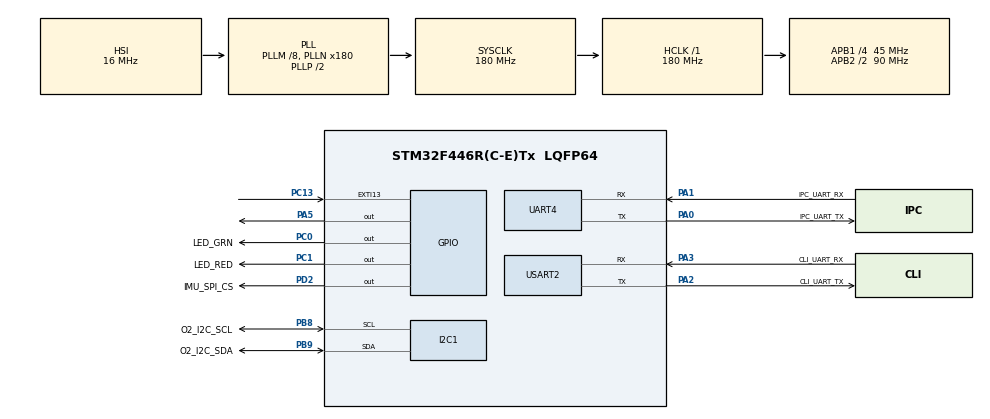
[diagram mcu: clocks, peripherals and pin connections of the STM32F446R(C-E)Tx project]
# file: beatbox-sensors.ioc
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Dma.I2C1_RX.3.Direction=DMA_PERIPH_TO_MEMORY
Dma.I2C1_RX.3.FIFOMode=DMA_FIFOMODE_DISABLE
Dma.I2C1_RX.3.Instance=DMA1_Stream0
Dma.I2C1_RX.3.MemDataAlignment=DMA_MDATAALIGN_BYTE
Dma.I2C1_RX.3.MemInc=DMA_MINC_ENABLE
Dma.I2C1_RX.3.Mode=DMA_NORMAL
Dma.I2C1_RX.3.PeriphDataAlignment=DMA_PDATAALIGN_BYTE
Dma.I2C1_RX.3.PeriphInc=DMA_PINC_DISABLE
Dma.I2C1_RX.3.Priority=DMA_PRIORITY_LOW
Dma.I2C1_TX.4.Direction=DMA_MEMORY_TO_PERIPH
Dma.I2C1_TX.4.FIFOMode=DMA_FIFOMODE_DISABLE
Dma.I2C1_TX.4.Instance=DMA1_Stream7
Dma.I2C1_TX.4.MemDataAlignment=DMA_MDATAALIGN_BYTE
Dma.I2C1_TX.4.MemInc=DMA_MINC_ENABLE
Dma.I2C1_TX.4.Mode=DMA_NORMAL
Dma.I2C1_TX.4.PeriphDataAlignment=DMA_PDATAALIGN_BYTE
Dma.I2C1_TX.4.PeriphInc=DMA_PINC_DISABLE
Dma.I2C1_TX.4.Priority=DMA_PRIORITY_LOW
Dma.Request0=USART2_RX
Dma.Request1=USART2_TX
Dma.Request2=UART4_TX
Dma.Request3=I2C1_RX
Dma.Request4=I2C1_TX
Dma.UART4_TX.2.Direction=DMA_MEMORY_TO_PERIPH
Dma.UART4_TX.2.FIFOMode=DMA_FIFOMODE_DISABLE
Dma.UART4_TX.2.Instance=DMA1_Stream4
Dma.UART4_TX.2.MemDataAlignment=DMA_MDATAALIGN_BYTE
Dma.UART4_TX.2.MemInc=DMA_MINC_ENABLE
Dma.UART4_TX.2.Mode=DMA_NORMAL
Dma.UART4_TX.2.PeriphDataAlignment=DMA_PDATAALIGN_BYTE
Dma.UART4_TX.2.PeriphInc=DMA_PINC_DISABLE
Dma.UART4_TX.2.Priority=DMA_PRIORITY_LOW
Dma.USART2_RX.0.Direction=DMA_PERIPH_TO_MEMORY
Dma.USART2_RX.0.FIFOMode=DMA_FIFOMODE_DISABLE
Dma.USART2_RX.0.Instance=DMA1_Stream5
Dma.USART2_RX.0.MemDataAlignment=DMA_MDATAALIGN_BYTE
Dma.USART2_RX.0.MemInc=DMA_MINC_ENABLE
Dma.USART2_RX.0.Mode=DMA_NORMAL
Dma.USART2_RX.0.PeriphDataAlignment=DMA_PDATAALIGN_BYTE
Dma.USART2_RX.0.PeriphInc=DMA_PINC_DISABLE
Dma.USART2_RX.0.Priority=DMA_PRIORITY_LOW
Dma.USART2_TX.1.Direction=DMA_MEMORY_TO_PERIPH
Dma.USART2_TX.1.FIFOMode=DMA_FIFOMODE_DISABLE
Dma.USART2_TX.1.Instance=DMA1_Stream6
Dma.USART2_TX.1.MemDataAlignment=DMA_MDATAALIGN_BYTE
Dma.USART2_TX.1.MemInc=DMA_MINC_ENABLE
Dma.USART2_TX.1.Mode=DMA_NORMAL
Dma.USART2_TX.1.PeriphDataAlignment=DMA_PDATAALIGN_BYTE
Dma.USART2_TX.1.PeriphInc=DMA_PINC_DISABLE
Dma.USART2_TX.1.Priority=DMA_PRIORITY_LOW
Mcu.Family=STM32F4
Mcu.Name=STM32F446R(C-E)Tx
Mcu.Package=LQFP64
NUCLEO-F446RE.BUTTON=1
NUCLEO-F446RE.LD1=true
NVIC.DMA1_Stream0_IRQn=true\:0\:0\:false\:false\:true\:false\:true\:true
NVIC.DMA1_Stream4_IRQn=true\:0\:0\:false\:false\:true\:false\:true\:true
NVIC.DMA1_Stream5_IRQn=true\:0\:0\:false\:false\:true\:false\:true\:true
NVIC.DMA1_Stream6_IRQn=true\:0\:0\:false\:false\:true\:false\:true\:true
NVIC.DMA1_Stream7_IRQn=true\:0\:0\:false\:false\:true\:false\:true\:true
NVIC.EXTI15_10_IRQn=true\:0\:0\:false\:false\:true\:false\:true\:true
NVIC.I2C1_ER_IRQn=true\:0\:0\:false\:false\:true\:true\:true\:true
NVIC.I2C1_EV_IRQn=true\:0\:0\:false\:false\:true\:true\:true\:true
NVIC.PriorityGroup=NVIC_PRIORITYGROUP_0
NVIC.UART4_IRQn=true\:0\:0\:false\:false\:true\:true\:true\:true
NVIC.USART2_IRQn=true\:0\:0\:false\:false\:true\:true\:true\:true
PA0-WKUP.GPIO_Label=IPC_UART_TX
PA0-WKUP.Mode=Asynchronous
PA0-WKUP.Signal=UART4_TX
PA1.GPIO_Label=IPC_UART_RX
PA1.Mode=Asynchronous
PA1.Signal=UART4_RX
PA13.GPIO_Label=TMS
PA13.Mode=Trace_Asynchronous_SW
PA13.Signal=SYS_JTMS-SWDIO
PA14.GPIO_Label=TCK
PA14.Mode=Trace_Asynchronous_SW
PA14.Signal=SYS_JTCK-SWCLK
PA2.GPIO_Label=CLI_UART_TX
PA2.Mode=Asynchronous
PA2.Signal=USART2_TX
PA3.GPIO_Label=CLI_UART_RX
PA3.Mode=Asynchronous
PA3.Signal=USART2_RX
PA5.Signal=GPIO_Output
PB3.GPIO_Label=SWO
PB3.Mode=Trace_Asynchronous_SW
PB3.Signal=SYS_JTDO-SWO
PB8.GPIO_Label=O2_I2C_SCL
PB8.Mode=I2C
PB8.Signal=I2C1_SCL
PB9.GPIO_Label=O2_I2C_SDA
PB9.Mode=I2C
PB9.Signal=I2C1_SDA
PC0.GPIO_Label=LED_GRN
PC0.Signal=GPIO_Output
PC1.GPIO_Label=LED_RED
PC1.Signal=GPIO_Output
PC10.GPIO_Label=IMU_SPI_CLK
PC10.Signal=SPI3_SCK
PC11.GPIO_Label=IMU_SPI_MISO
PC11.Signal=SPI3_MISO
PC12.GPIO_Label=IMU_SPI_MOSI
PC12.Signal=SPI3_MOSI
PC13.Signal=GPXTI13
PD2.GPIO_Label=IMU_SPI_CS
PD2.Signal=GPIO_Output
ProjectManager.HeapSize=0x200
ProjectManager.StackSize=0x400
ProjectManager.TargetToolchain=CMake
RCC.AHBFreq_Value=180000000
RCC.APB1CLKDivider=RCC_HCLK_DIV4
RCC.APB1Freq_Value=45000000
RCC.APB1TimFreq_Value=90000000
RCC.APB2CLKDivider=RCC_HCLK_DIV2
RCC.APB2Freq_Value=90000000
RCC.APB2TimFreq_Value=180000000
RCC.CortexFreq_Value=180000000
RCC.FLatency-AdvancedSettings=FLASH_LATENCY_5
RCC.HCLKFreq_Value=180000000
RCC.HSE_VALUE=8000000
RCC.HSI_VALUE=16000000
RCC.LSE_VALUE=32768
RCC.PLLM=8
RCC.PLLN=180
RCC.SYSCLKFreq_VALUE=180000000
RCC.SYSCLKSource=RCC_SYSCLKSOURCE_PLLCLK
RCC.USBFreq_Value=180000000
RCC.VCOOutputFreq_Value=360000000
UART4.VirtualMode=Asynchronous
USART2.VirtualMode=VM_ASYNC
VP_NUCLEO-F446RE_VS_BSP_COMMON.Mode=COMMON
board=NUCLEO-F446RE

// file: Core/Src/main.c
/* USER CODE BEGIN Header */
/**
 ******************************************************************************
 * @file           : main.c
 * @brief          : Main program body
 ******************************************************************************
 * @attention
 *
 * Copyright (c) 2026 STMicroelectronics.
 * All rights reserved.
 *
 * This software is licensed under terms that can be found in the LICENSE file
 * in the root directory of this software component.
 * If no LICENSE file comes with this software, it is provided AS-IS.
 *
 ******************************************************************************
 */
/* USER CODE END Header */
#include "main.h"
#include "dma.h"
#include "i2c.h"
#include "usart.h"
#include "gpio.h"

/* USER CODE BEGIN Includes */
#include "app/app.hpp"
/* USER CODE END Includes */

void SystemClock_Config(void);

int main(void)
{

  /* MCU Configuration--------------------------------------------------------*/

  /* Reset of all peripherals, Initializes the Flash interface and the Systick. */
  HAL_Init();

  /* Configure the system clock */
  SystemClock_Config();

  /* Initialize all configured peripherals */
  MX_GPIO_Init();
  MX_DMA_Init();
  MX_I2C1_Init();
  MX_USART2_UART_Init();
  MX_UART4_Init();
  /* USER CODE BEGIN 2 */
  appInit();
  /* USER CODE END 2 */

  /* Initialize leds */
  BSP_LED_Init(LED2);

  /* Initialize USER push-button, will be used to trigger an interrupt each time it's pressed.*/
  BSP_PB_Init(BUTTON_USER, BUTTON_MODE_EXTI);

  /* Infinite loop */
  /* USER CODE BEGIN WHILE */
  while (1) {
    appRun();
    /* USER CODE END WHILE */

  }
}

void SystemClock_Config(void)
{
  RCC_OscInitTypeDef RCC_OscInitStruct = {0};
  RCC_ClkInitTypeDef RCC_ClkInitStruct = {0};

  /** Configure the main internal regulator output voltage
  */
  __HAL_RCC_PWR_CLK_ENABLE();
  __HAL_PWR_VOLTAGESCALING_CONFIG(PWR_REGULATOR_VOLTAGE_SCALE1);

  /** Initializes the RCC Oscillators according to the specified parameters
  * in the RCC_OscInitTypeDef structure.
  */
  RCC_OscInitStruct.OscillatorType = RCC_OSCILLATORTYPE_HSI;
  RCC_OscInitStruct.HSIState = RCC_HSI_ON;
  RCC_OscInitStruct.HSICalibrationValue = RCC_HSICALIBRATION_DEFAULT;
  RCC_OscInitStruct.PLL.PLLState = RCC_PLL_ON;
  RCC_OscInitStruct.PLL.PLLSource = RCC_PLLSOURCE_HSI;
  RCC_OscInitStruct.PLL.PLLM = 8;
  RCC_OscInitStruct.PLL.PLLN = 180;
  RCC_OscInitStruct.PLL.PLLP = RCC_PLLP_DIV2;
  RCC_OscInitStruct.PLL.PLLQ = 2;
  RCC_OscInitStruct.PLL.PLLR = 2;
  if (HAL_RCC_OscConfig(&RCC_OscInitStruct) != HAL_OK)
  {
    Error_Handler();
  }

  /** Activate the Over-Drive mode
  */
  if (HAL_PWREx_EnableOverDrive() != HAL_OK)
  {
    Error_Handler();
  }

  /** Initializes the CPU, AHB and APB buses clocks
  */
  RCC_ClkInitStruct.ClockType = RCC_CLOCKTYPE_HCLK|RCC_CLOCKTYPE_SYSCLK
                              |RCC_CLOCKTYPE_PCLK1|RCC_CLOCKTYPE_PCLK2;
  RCC_ClkInitStruct.SYSCLKSource = RCC_SYSCLKSOURCE_PLLCLK;
  RCC_ClkInitStruct.AHBCLKDivider = RCC_SYSCLK_DIV1;
  RCC_ClkInitStruct.APB1CLKDivider = RCC_HCLK_DIV4;
  RCC_ClkInitStruct.APB2CLKDivider = RCC_HCLK_DIV2;

  if (HAL_RCC_ClockConfig(&RCC_ClkInitStruct, FLASH_LATENCY_5) != HAL_OK)
  {
    Error_Handler();
  }
}

void Error_Handler(void)
{
  /* USER CODE BEGIN Error_Handler_Debug */
  /* User can add his own implementation to report the HAL error return state */
  __disable_irq();
  for (;;) {
    HAL_GPIO_TogglePin(LED2_GPIO_PORT, LED2_PIN);

    for (volatile uint32_t i = 0; i < 2000000; i++)
      ;
  }
  /* USER CODE END Error_Handler_Debug */
}
#ifdef USE_FULL_ASSERT
/**
  * @brief  Reports the name of the source file and the source line number
  *         where the assert_param error has occurred.
  * @param  file: pointer to the source file name
  * @param  line: assert_param error line source number
  * @retval None
  */
void assert_failed(uint8_t *file, uint32_t line)
{
  /* USER CODE BEGIN 6 */
  /* User can add his own implementation to report the file name and line
     number, ex: printf("Wrong parameters value: file %s on line %d\r\n", file,
     line) */
  /* USER CODE END 6 */
}
#endif /* USE_FULL_ASSERT */
